# VPAC0_PAR_VPAC_NF_S_VBUSP_MMR_VBUSP_NF_CFG register map
Vendor: Texas Instruments
Peripheral module from a debugger description file (folder J721S2).
Registers are 32-bit, access not given, reset 0x0 unless marked. A register's access mark holds for its fields unless they carry their own. Offsets are as the file gives them; lines under a group give offsets from that group; [hi:lo] are bit positions; {n}, {i} and the like mark numbered series; 'fields as' and 'values as' point back to an identical list; <NAME> marks a mode.

## VPAC0_PAR_VPAC_NF_S_VBUSP_MMR_VBUSP_NF_CFG
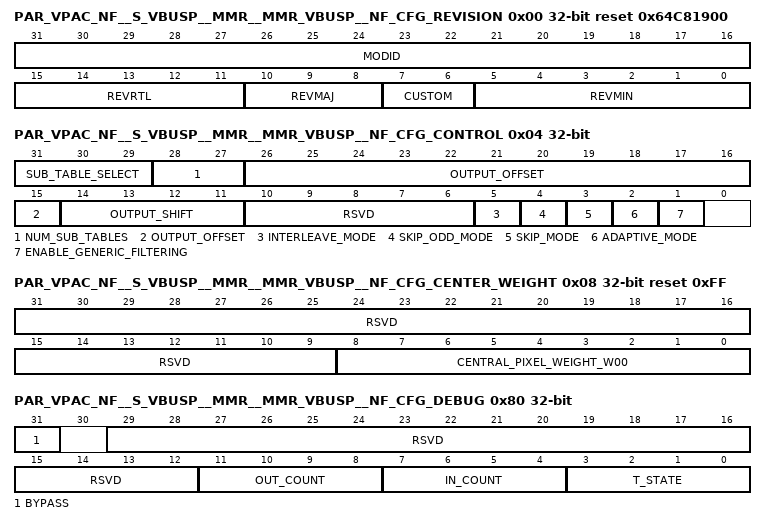
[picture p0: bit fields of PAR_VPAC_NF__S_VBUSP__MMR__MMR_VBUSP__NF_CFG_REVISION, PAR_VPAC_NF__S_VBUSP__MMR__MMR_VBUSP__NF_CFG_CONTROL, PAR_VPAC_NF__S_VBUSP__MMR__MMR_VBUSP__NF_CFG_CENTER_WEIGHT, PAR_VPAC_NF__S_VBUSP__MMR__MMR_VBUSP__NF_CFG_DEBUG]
0x00 PAR_VPAC_NF__S_VBUSP__MMR__MMR_VBUSP__NF_CFG_REVISION ro reset 0x64C81900 — The Revision Register contains the major and minor revisions for the module.
  [31:16] MODID — Module ID field
  [15:11] REVRTL — RTL revision. Will vary depending on release.
  [10:8] REVMAJ — Major revision
  [7:6] CUSTOM
  [5:0] REVMIN — Minor revision
0x04 PAR_VPAC_NF__S_VBUSP__MMR__MMR_VBUSP__NF_CFG_CONTROL — This contains parameters to control NF Core
  [31:29] SUB_TABLE_SELECT rw — Defines which sub table is used statically. Only valid when adaptive_mode is disabled This allows the SW to statically define which sub table to use throughout the frame. SW must set this before the first line of the frame 0 = sub Table 0 selected 1 = sub Table 1 selected . 7 = sub Table 7 selected
  [28:27] NUM_SUB_TABLES rw — Defines the number of sub-tables 0 = 1 table 1 = 2 sub tables 2 = 4 sub tables 3 = 8 sub tables
  [26:15] OUTPUT_OFFSET rw — unsigned offset value to added to output after shifting and before clipping
  [14:11] OUTPUT_SHIFT rw — Signed 4 bit (24 is added before using it inside IP)
  [10:6] RSVD — Always read as 0. Writes have no affect
  [5] INTERLEAVE_MODE rw — Interleave Mode. 0 = Disabled 1 = Enabled
  [4] SKIP_ODD_MODE rw — Skip Odd Mode. 0 = Disabled 1 = Enabled
  [3] SKIP_MODE rw — Skip Mode. 0 = Disabled 1 = Enabled
  [2] ADAPTIVE_MODE rw — Defines what controls the selection of the sub table. 0 = Bi-lateral filtering Adaptive mode is Disabled and sub_table_select defines which sub table is used 1 = Bi-lateral filtering Adaptive mode is Enabled and the 4x4 avg is used to determine which sub table is used
  [1] ENABLE_GENERIC_FILTERING rw — Filter mode, 0=> Bi-lateral filtering, 1= Generic 2D Filtering
0x08 PAR_VPAC_NF__S_VBUSP__MMR__MMR_VBUSP__NF_CFG_CENTER_WEIGHT reset 0xFF — Contain center weight parameter
  [31:9] RSVD — Always read as 0. Writes have no affect
  [8:0] CENTRAL_PIXEL_WEIGHT_W00 rw — Central pixel weight, 8 bit unsigned in Bi-lateral filtering, 9 bit signed in Generic 2D Filtering
0x80 PAR_VPAC_NF__S_VBUSP__MMR__MMR_VBUSP__NF_CFG_DEBUG — Debug
  [31] BYPASS rw — Bypass Mode When enabled output equals the input , namely C2_R0 input matrix
  [29:12] RSVD — Always read as 0. Writes have no affect
  [11:8] OUT_COUNT ro — output free running counter , gets reset on start of line
  [7:4] IN_COUNT ro — input free running counter , gets reset on start of line
  [3:0] T_STATE ro — StateMachine State
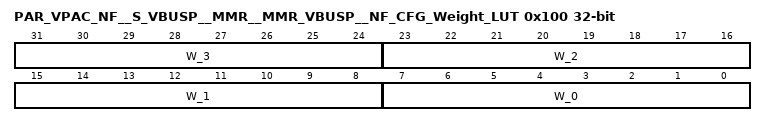
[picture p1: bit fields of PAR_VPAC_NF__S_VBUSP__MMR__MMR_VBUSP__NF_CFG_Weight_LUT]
0x100 PAR_VPAC_NF__S_VBUSP__MMR__MMR_VBUSP__NF_CFG_Weight_LUT rw — This contains weights for LUT. These acts as 1280 size LUT (8 bit each) in Bi-lateral mode, while 24 size (9 bit in 16 bit container) in Generic Filtering mode
  [8n+7:8n] W_{n} (n=0..3) — weight W_{n}
